# ESP32S31_RADIO register map
Vendor: Espressif; Series: ESP32-S31; File version: 3.52
Registers are 32-bit, read-write, no defined reset value unless marked. A register's access mark holds for its fields unless they carry their own. Offsets are from the block's base; [hi:lo] are bit positions; {n}, {i} and the like mark numbered series.

## PHY_FREQUENCY_CHANNEL_ORACLE — Frequency-memory, hardware channel-switch, NRX and channel-bandwidth registers recovered from complete finite ROM/blob bodies. Names retain UNKNOWN where the instructions prove a field but not its electrical meaning. One physical word has one identity even when a bit has different mode-dependent roles.
Base 0x20100000
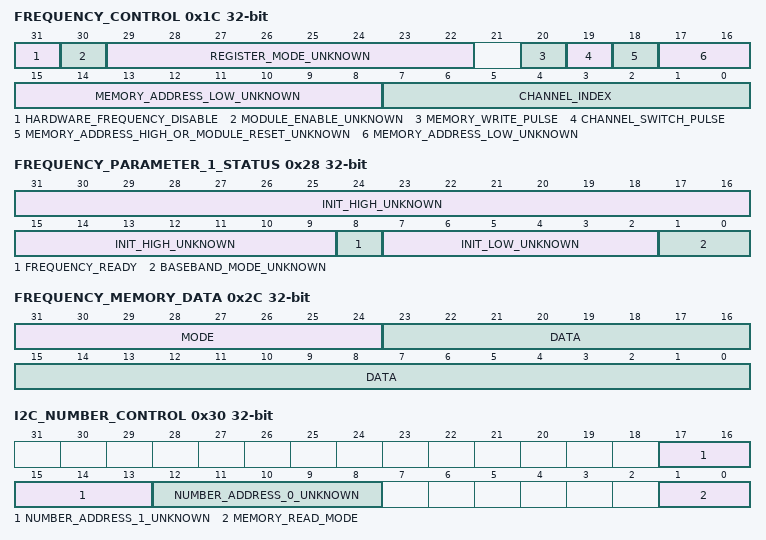
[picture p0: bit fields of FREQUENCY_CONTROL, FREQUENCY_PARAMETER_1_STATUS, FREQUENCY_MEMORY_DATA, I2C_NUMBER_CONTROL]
0x1C FREQUENCY_CONTROL — Shared frequency module control word. Bit 18 is both the high bit of an eleven-bit command-memory address and the reset/release bit pulsed by phy_freq_module_resetn.
  [31] HARDWARE_FREQUENCY_DISABLE — Complete phy_dis_hw_set_freq sets bit 31 before its two-microsecond delay; complete phy_en_hw_set_freq clears it.
  [30] MODULE_ENABLE_UNKNOWN — Complete phy_freq_reg_init sets bit 30.
  [29:22] REGISTER_MODE_UNKNOWN — Complete phy_freq_reg_init replaces bits 29:22 with its two input nibbles; the electrical encoding is unknown.
  [20] MEMORY_WRITE_PULSE — Complete phy_freq_i2c_mem_write sets then clears bit 20 after publishing data.
  [19] CHANNEL_SWITCH_PULSE — Complete phy_freq_chan_en_sw sets bit 19, delays one microsecond, then clears it.
  [18] MEMORY_ADDRESS_HIGH_OR_MODULE_RESET_UNKNOWN — High address bit during frequency-memory writes; independently cleared then set by complete phy_freq_module_resetn.
  [17:8] MEMORY_ADDRESS_LOW_UNKNOWN — Low ten bits of the eleven-bit address selected by phy_freq_i2c_mem_write.
  [7:0] CHANNEL_INDEX — Complete phy_freq_chan_en_sw replaces the low byte with the caller's frequency-table index.
0x20 FREQUENCY_MEMORY_READ_CONTROL — Complete phy_read_rf_freq_mem pulses bit 16 after publishing the address and read mode; all other bits remain preserved and unnamed.
  [16] READ_PULSE — Set and then cleared by complete phy_read_rf_freq_mem for one synchronous frequency-memory read transaction.
0x24 FREQUENCY_PARAMETER_0_OPAQUE wo — Complete phy_freq_reg_init writes the full constant 0x19800249; no constituent electrical fields are public.
  [31:0] OPAQUE_VALUE
0x28 FREQUENCY_PARAMETER_1_STATUS — Complete phy_freq_reg_init writes 0x25824e58; phy_bb_init replaces the low baseband-mode field, and the open channel state machine samples bit 8 for the evidenced ready edge.
  [31:9] INIT_HIGH_UNKNOWN — Bits 31:9 of the complete initialization image.
  [8] FREQUENCY_READY ro — The complete channel parent samples bit 8 after the frequency-switch delay and branches on its asserted edge.
  [7:2] INIT_LOW_UNKNOWN — Bits 7:2 of the complete initialization image.
  [1:0] BASEBAND_MODE_UNKNOWN — Complete phy_bb_init writes encoding two before calibration and zero after the initial channel setup.
0x2C FREQUENCY_MEMORY_DATA wo — Data/mode word published by complete phy_freq_i2c_mem_write.
  [31:24] MODE, [23:0] DATA
0x30 I2C_NUMBER_CONTROL — First two five-bit PHY-I2C number addresses packed by complete phy_freq_i2c_num_addr.
  [17:13] NUMBER_ADDRESS_1_UNKNOWN
  [12:8] NUMBER_ADDRESS_0_UNKNOWN
  [1:0] MEMORY_READ_MODE — Complete phy_read_rf_freq_mem replaces only the low two bits with its read-mode argument.
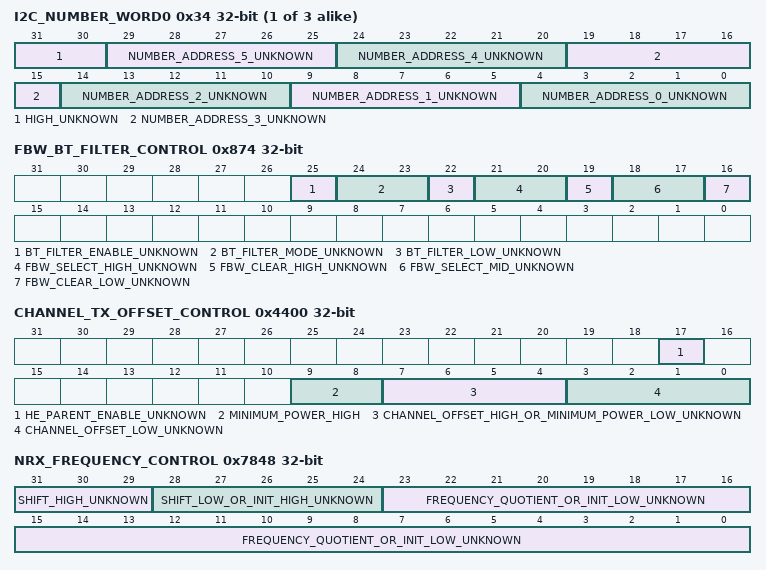
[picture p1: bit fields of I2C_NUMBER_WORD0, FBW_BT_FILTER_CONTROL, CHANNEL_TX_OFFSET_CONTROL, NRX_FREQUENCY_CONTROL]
{0x34+4i} I2C_NUMBER_WORD{i} (i=0..2) wo — Six consecutive five-bit PHY-I2C number addresses packed by complete phy_freq_num_get_data; unused slots are zero.
  [31:30] HIGH_UNKNOWN — High two bits of the complete caller-prepared word; the recovered producer normally leaves them zero.
  [5n+4:5n] NUMBER_ADDRESS_{n}_UNKNOWN (n=0..5)
0x40 FREQUENCY_MEMORY_READ_RESULT ro — Complete phy_read_rf_freq_mem returns this full word after the read pulse; individual result fields are interpreted by the caller.
  [31:0] VALUE — Complete phy_read_rf_freq_mem returns this full read-only result to its caller.
0x874 FBW_BT_FILTER_CONTROL — Shared filter-bandwidth and Bluetooth-filter word independently updated by complete phy_wifi_fbw_sel and phy_bt_filter_reg.
  [25] BT_FILTER_ENABLE_UNKNOWN, [24:23] BT_FILTER_MODE_UNKNOWN, [22] BT_FILTER_LOW_UNKNOWN, [21:20] FBW_SELECT_HIGH_UNKNOWN, [19] FBW_CLEAR_HIGH_UNKNOWN, [18:17] FBW_SELECT_MID_UNKNOWN, [16] FBW_CLEAR_LOW_UNKNOWN
0x4400 CHANNEL_TX_OFFSET_CONTROL — Canonical multifunction PHY/MAC word. Complete phy_mac_tx_chan_offset and phy_bb_cbw_chan_cfg update the low channel-offset field; complete hal_set_tx_min_pwr updates bits 9:4 and the HE init parent independently sets bit 17.
  [17] HE_PARENT_ENABLE_UNKNOWN — The complete HE init parent sets bit 17 through a separate fresh-read RMW.
  [9:8] MINIMUM_POWER_HIGH — High two bits of the signed six-bit minimum-power value. Complete hal_set_tx_min_pwr(-11) writes three.
  [7:4] CHANNEL_OFFSET_HIGH_OR_MINIMUM_POWER_LOW_UNKNOWN — Complete phy_bb_cbw_chan_cfg clears this shared nibble as the high half of its normalized channel-offset byte. Complete hal_set_tx_min_pwr(-11) independently writes the low nibble of signed six-bit value 0x35 here.
  [3:0] CHANNEL_OFFSET_LOW_UNKNOWN
0x7848 NRX_FREQUENCY_CONTROL — NRX initialization and frequency quotient word. Complete phy_nrx_freq_set samples and preserves the high byte and writes a twenty-four-bit quotient. Initialization writes the same complete low twenty-four-bit region with its own image.
  [31:29] SHIFT_HIGH_UNKNOWN, [28:24] SHIFT_LOW_OR_INIT_HIGH_UNKNOWN, [23:0] FREQUENCY_QUOTIENT_OR_INIT_LOW_UNKNOWN
0x7CE0 CHANNEL_CBW_CONTROL_0 — Complete phy_bb_cbw_chan_cfg replaces the low two-bit CBW-derived field.
  [1:0] CBW_LOW_UNKNOWN
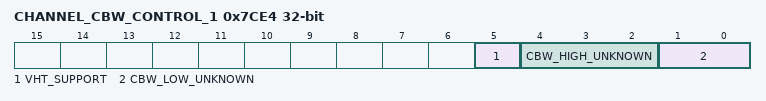
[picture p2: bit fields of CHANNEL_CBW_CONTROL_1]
0x7CE4 CHANNEL_CBW_CONTROL_1 — Complete phy_bb_cbw_chan_cfg performs two fresh-read CBW-derived replacements; complete phy_vht_support independently replaces bit five.
  [5] VHT_SUPPORT, [4:2] CBW_HIGH_UNKNOWN, [1:0] CBW_LOW_UNKNOWN
